# PIC16HV753 register map
Vendor: Microchip
Registers are 8-bit, read-write, reset 0x0 unless marked. A register's access mark holds for its fields unless they carry their own. Addresses are absolute, and some are shared; only a register's first bit layout is shown; [hi:lo] are bit positions; {n}, {i} and the like mark numbered series.

## SFR
0x00 INDF access not given reset not defined — (power-on value xxxxxxxx)
0x01 TMR0 reset not defined — (power-on value xxxxxxxx)
0x02 PCL
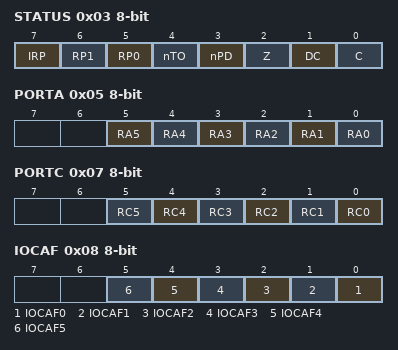
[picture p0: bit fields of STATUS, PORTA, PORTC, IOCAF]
0x03 STATUS reset not defined — (power-on value 00011xxx)
  [7] IRP, [6] RP1, [5] RP0, [4] nTO ro, [3] nPD ro, [2] Z, [1] DC, [0] C
0x04 FSR reset not defined — (power-on value xxxxxxxx)
0x05 PORTA reset not defined — (power-on value --xxxxxx)
  [5] RA5, [4] RA4, [3] RA3 ro, [2] RA2, [1] RA1, [0] RA0
0x07 PORTC reset not defined — (power-on value --uuuuuu)
  [n] RC{n} (n=0..5)
0x08 IOCAF
  [n] IOCAF{n} (n=0..5)
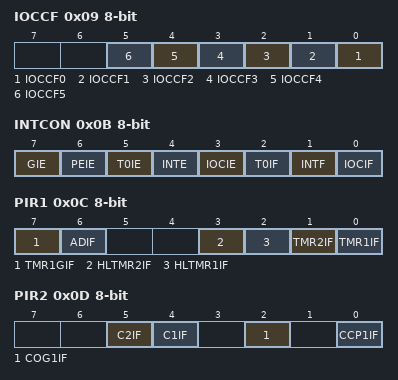
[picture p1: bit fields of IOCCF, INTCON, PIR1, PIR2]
0x09 IOCCF
  [n] IOCCF{n} (n=0..5)
0x0A PCLATH
  [4:0] PCLATH
0x0B INTCON
  [7] GIE, [6] PEIE, [5] T0IE, [4] INTE, [3] IOCIE, [2] T0IF, [1] INTF, [0] IOCIF
0x0C PIR1
  [7] TMR1GIF, [6] ADIF, [3] HLTMR2IF, [2] HLTMR1IF, [1] TMR2IF, [0] TMR1IF
0x0D PIR2
  [5] C2IF, [4] C1IF, [2] COG1IF, [0] CCP1IF
0x0F TMR1L reset not defined — (power-on value xxxxxxxx)
0x10 TMR1H reset not defined — (power-on value xxxxxxxx)
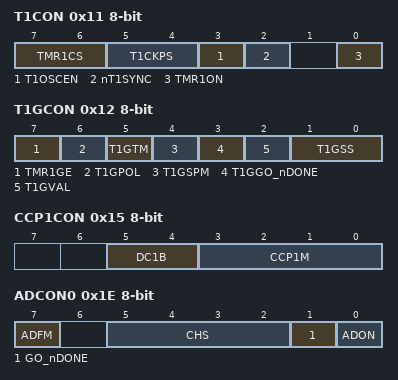
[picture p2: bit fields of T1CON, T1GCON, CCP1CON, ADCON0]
0x11 T1CON
  [7:6] TMR1CS, [5:4] T1CKPS, [3] T1OSCEN, [2] nT1SYNC, [0] TMR1ON
0x12 T1GCON reset not defined — (power-on value 00000x00)
  [7] TMR1GE, [6] T1GPOL, [5] T1GTM, [4] T1GSPM, [3] T1GGO_nDONE, [2] T1GVAL ro, [1:0] T1GSS
0x13 CCPR1L reset not defined — (power-on value xxxxxxxx)
0x14 CCPR1H reset not defined — (power-on value xxxxxxxx)
0x15 CCP1CON
  [5:4] DC1B, [3:0] CCP1M
0x1C ADRESL reset not defined — A/D Result Register LSB (power-on value xxxxxxxx)
0x1D ADRESH reset not defined — A/D Result Register MSB (power-on value xxxxxxxx)
0x1E ADCON0
  [7] ADFM, [5:2] CHS, [1] GO_nDONE, [0] ADON
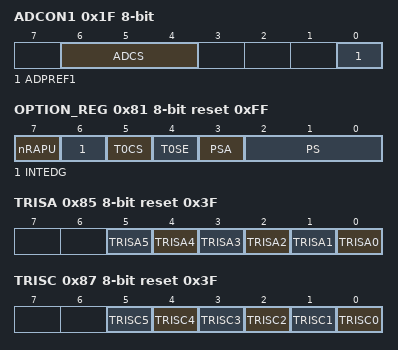
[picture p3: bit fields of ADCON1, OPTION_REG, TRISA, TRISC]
0x1F ADCON1
  [6:4] ADCS, [0] ADPREF1
0x81 OPTION_REG reset 0xFF
  [7] nRAPU, [6] INTEDG, [5] T0CS, [4] T0SE, [3] PSA, [2:0] PS
0x85 TRISA reset 0x3F
  [n] TRISA{n} (n=0..5)
0x87 TRISC reset 0x3F
  [n] TRISC{n} (n=0..5)
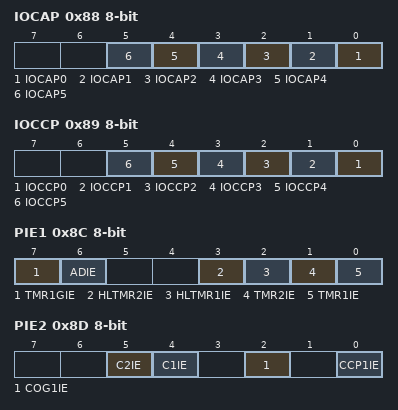
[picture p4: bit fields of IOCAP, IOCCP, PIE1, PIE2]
0x88 IOCAP
  [n] IOCAP{n} (n=0..5)
0x89 IOCCP
  [n] IOCCP{n} (n=0..5)
0x8C PIE1
  [7] TMR1GIE, [6] ADIE, [3] HLTMR2IE, [2] HLTMR1IE, [1] TMR2IE, [0] TMR1IE
0x8D PIE2
  [5] C2IE, [4] C1IE, [2] COG1IE, [0] CCP1IE
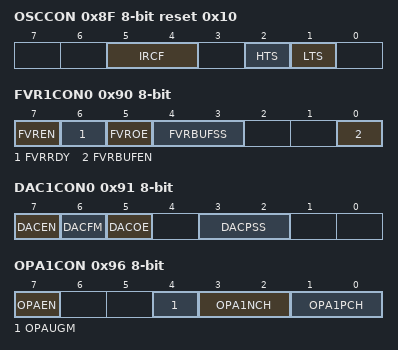
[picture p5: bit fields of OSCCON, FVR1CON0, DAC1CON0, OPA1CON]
0x8F OSCCON reset 0x10
  [5:4] IRCF, [2] HTS, [1] LTS
0x90 FVR1CON0
  [7] FVREN, [6] FVRRDY, [5] FVROE, [4:3] FVRBUFSS, [0] FVRBUFEN
0x91 DAC1CON0 reset not defined — (power-on value 000-xx--)
  [7] DACEN, [6] DACFM, [5] DACOE, [3:2] DACPSS
0x92 DAC1REFL
  [7:0] DACR
0x93 DAC1REFH
  [7:0] DACR
0x96 OPA1CON
  [7] OPAEN, [4] OPAUGM, [3:2] OPA1NCH, [1:0] OPA1PCH
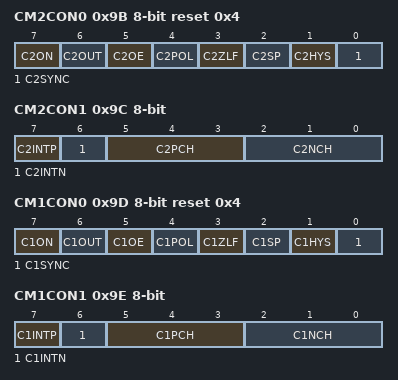
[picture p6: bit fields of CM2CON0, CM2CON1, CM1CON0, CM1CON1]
0x9B CM2CON0 reset 0x4
  [7] C2ON, [6] C2OUT, [5] C2OE, [4] C2POL, [3] C2ZLF, [2] C2SP, [1] C2HYS, [0] C2SYNC
0x9C CM2CON1
  [7] C2INTP, [6] C2INTN, [5:3] C2PCH, [2:0] C2NCH
0x9D CM1CON0 reset 0x4
  [7] C1ON, [6] C1OUT, [5] C1OE, [4] C1POL, [3] C1ZLF, [2] C1SP, [1] C1HYS, [0] C1SYNC
0x9E CM1CON1
  [7] C1INTP, [6] C1INTN, [5:3] C1PCH, [2:0] C1NCH
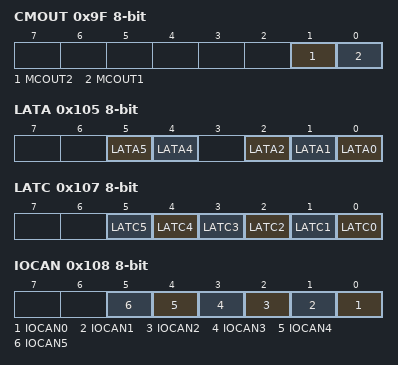
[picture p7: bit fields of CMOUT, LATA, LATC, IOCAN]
0x9F CMOUT
  [1] MCOUT2, [0] MCOUT1
0x105 LATA reset not defined — (power-on value --xx-xxx)
  [5] LATA5, [4] LATA4, [2] LATA2, [1] LATA1, [0] LATA0
0x107 LATC reset not defined — (power-on value --xxxxxx)
  [n] LATC{n} (n=0..5)
0x108 IOCAN
  [n] IOCAN{n} (n=0..5)
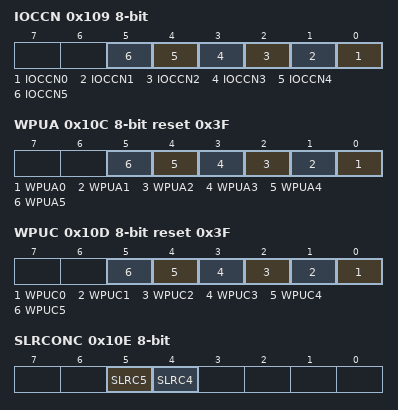
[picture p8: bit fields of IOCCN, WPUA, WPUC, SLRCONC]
0x109 IOCCN
  [n] IOCCN{n} (n=0..5)
0x10C WPUA reset 0x3F
  [n] WPUA{n} (n=0..5)
0x10D WPUC reset 0x3F
  [n] WPUC{n} (n=0..5)
0x10E SLRCONC
  [5] SLRC5, [4] SLRC4
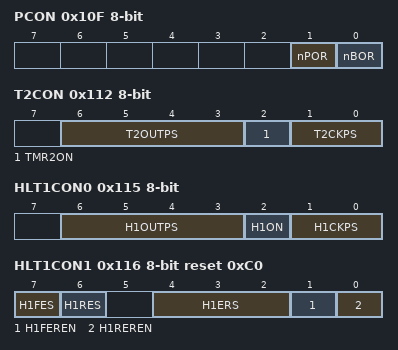
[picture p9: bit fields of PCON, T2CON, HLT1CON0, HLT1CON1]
0x10F PCON reset not defined — (power-on value ------qq)
  [1] nPOR, [0] nBOR
0x110 TMR2
0x111 PR2 reset 0xFF
0x112 T2CON
  [6:3] T2OUTPS, [2] TMR2ON, [1:0] T2CKPS
0x113 HLTMR1
0x114 HLTPR1 reset 0xFF
0x115 HLT1CON0
  [6:3] H1OUTPS, [2] H1ON, [1:0] H1CKPS
0x116 HLT1CON1 reset 0xC0
  [7] H1FES, [6] H1RES, [4:2] H1ERS, [1] H1FEREN, [0] H1REREN
0x117 HLTMR2
0x118 HLTPR2 reset 0xFF
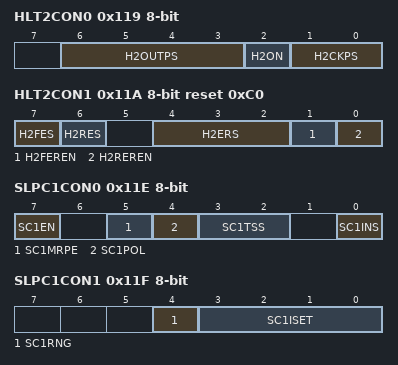
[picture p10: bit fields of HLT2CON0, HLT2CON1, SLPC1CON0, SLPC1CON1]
0x119 HLT2CON0
  [6:3] H2OUTPS, [2] H2ON, [1:0] H2CKPS
0x11A HLT2CON1 reset 0xC0
  [7] H2FES, [6] H2RES, [4:2] H2ERS, [1] H2FEREN, [0] H2REREN
0x11E SLPC1CON0
  [7] SC1EN, [5] SC1MRPE, [4] SC1POL, [3:2] SC1TSS, [0] SC1INS
0x11F SLPC1CON1
  [4] SC1RNG, [3:0] SC1ISET
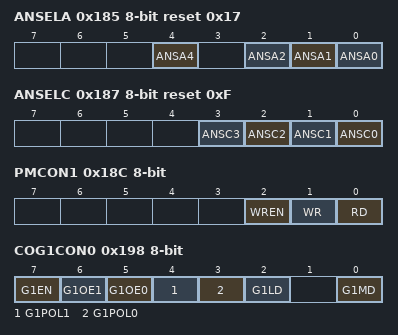
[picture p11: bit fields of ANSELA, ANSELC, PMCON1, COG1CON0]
0x185 ANSELA reset 0x17
  [4] ANSA4, [2] ANSA2, [1] ANSA1, [0] ANSA0
0x187 ANSELC reset 0xF
  [n] ANSC{n} (n=0..3)
0x188 APFCON
  [4] T1GSEL
0x189 OSCTUNE
  [4:0] TUN
0x18C PMCON1
  [2] WREN — Program/Erase Enable bit
  [1] WR — Write Control bit (can only be set)
  [0] RD — Read Control bit (can only be set)
0x18D PMCON2 wo reset not defined
0x18E PMADRL
0x18F PMADRH
  [2:0] PMADRH
0x190 PMDATL
0x191 PMDATH
  [5:0] PMDATH
0x192 COG1PHR reset not defined — (power-on value ----xxxx)
  [3:0] G1PHR
0x193 COG1PHF reset not defined — (power-on value ----xxxx)
  [3:0] G1PHF
0x194 COG1BKR reset not defined — (power-on value ----xxxx)
  [3:0] G1BKR
0x195 COG1BKF reset not defined — (power-on value ----xxxx)
  [3:0] G1BKF
0x196 COG1DBR reset not defined — (power-on value ----xxxx)
  [3:0] G1DBR
0x197 COG1DBF reset not defined — (power-on value ----xxxx)
  [3:0] G1DBF
0x198 COG1CON0
  [7] G1EN, [6] G1OE1, [5] G1OE0, [4] G1POL1, [3] G1POL0, [2] G1LD, [0] G1MD
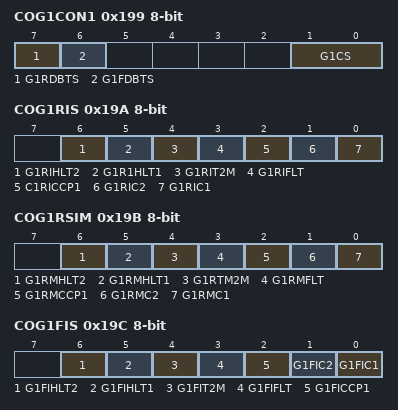
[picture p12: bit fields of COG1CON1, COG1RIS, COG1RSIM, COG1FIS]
0x199 COG1CON1
  [7] G1RDBTS, [6] G1FDBTS, [1:0] G1CS
0x19A COG1RIS
  [6] G1RIHLT2, [5] G1R1HLT1, [4] G1RIT2M, [3] G1RIFLT, [2] C1RICCP1, [1] G1RIC2, [0] G1RIC1
0x19B COG1RSIM
  [6] G1RMHLT2, [5] G1RMHLT1, [4] G1RTM2M, [3] G1RMFLT, [2] G1RMCCP1, [1] G1RMC2, [0] G1RMC1
0x19C COG1FIS
  [6] G1FIHLT2, [5] G1FIHLT1, [4] G1FIT2M, [3] G1FIFLT, [2] G1FICCP1, [1] G1FIC2, [0] G1FIC1
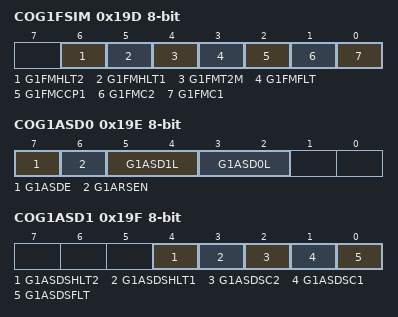
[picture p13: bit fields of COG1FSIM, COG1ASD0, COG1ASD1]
0x19D COG1FSIM
  [6] G1FMHLT2, [5] G1FMHLT1, [4] G1FMT2M, [3] G1FMFLT, [2] G1FMCCP1, [1] G1FMC2, [0] G1FMC1
0x19E COG1ASD0
  [7] G1ASDE, [6] G1ARSEN, [5:4] G1ASD1L, [3:2] G1ASD0L
0x19F COG1ASD1
  [4] G1ASDSHLT2, [3] G1ASDSHLT1, [2] G1ASDSC2, [1] G1ASDSC1, [0] G1ASDSFLT
